# CONTROLSS_OUTPUTXBAR_CONTROLSS_OUTPUTXBAR register map
Vendor: Texas Instruments
Peripheral module from a debugger description file (folder AM263).
Registers are 32-bit, read-write, reset 0x0 unless marked. A register's access mark holds for its fields unless they carry their own. Offsets are as the file gives them; lines under a group give offsets from that group; [hi:lo] are bit positions; {n}, {i} and the like mark numbered series; 'fields as' and 'values as' point back to an identical list; <NAME> marks a mode.

## CONTROLSS_OUTPUTXBAR_CONTROLSS_OUTPUTXBAR
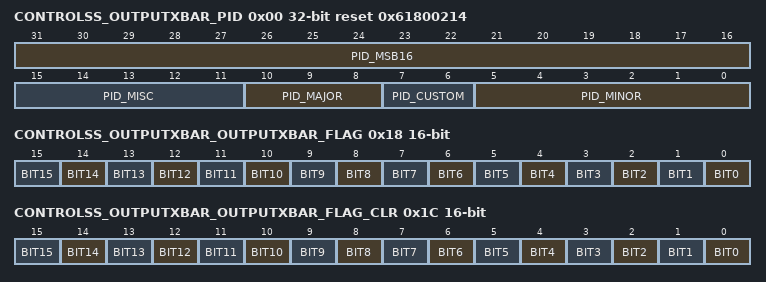
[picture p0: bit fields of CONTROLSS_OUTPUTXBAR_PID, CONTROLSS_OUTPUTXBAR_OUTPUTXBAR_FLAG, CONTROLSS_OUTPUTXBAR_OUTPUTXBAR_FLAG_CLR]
0x00 CONTROLSS_OUTPUTXBAR_PID ro reset 0x61800214
  [31:16] PID_MSB16 — Not Defined
  [15:11] PID_MISC — Not Defined
  [10:8] PID_MAJOR — Not Defined
  [7:6] PID_CUSTOM — Not Defined
  [5:0] PID_MINOR — Not Defined
0x10 CONTROLSS_OUTPUTXBAR_OUTPUTXBAR_STATUS 16-bit ro
  [15:0] STS — Status
0x14 CONTROLSS_OUTPUTXBAR_OUTPUTXBAR_FLAGINVERT 16-bit
  [15:0] INVERT — FlagInvert
0x18 CONTROLSS_OUTPUTXBAR_OUTPUTXBAR_FLAG 16-bit
  [n] BIT{n} (n=0..15) — output xbar flag
0x1C CONTROLSS_OUTPUTXBAR_OUTPUTXBAR_FLAG_CLR 16-bit
  [n] BIT{n} (n=0..15) — output xbar flag clear
0x20 CONTROLSS_OUTPUTXBAR_OUTPUTXBAR_FLAGFORCE 16-bit
  [15:0] FRC — FlagForce
0x24 CONTROLSS_OUTPUTXBAR_OUTPUTXBAR_OUTLATCH 16-bit
  [15:0] LATCHSEL — OutLatch
0x28 CONTROLSS_OUTPUTXBAR_OUTPUTXBAR_OUTSTRETCH 16-bit
  [15:0] STRETCHSEL — OutStretch
0x2C CONTROLSS_OUTPUTXBAR_OUTPUTXBAR_OUTLENGTH 16-bit
  [15:0] LENGTHSEL — OutLength
0x30 CONTROLSS_OUTPUTXBAR_OUTPUTXBAR_OUTINVERT 16-bit
{0x100+0x40*i} CONTROLSS_OUTPUTXBAR_OUTPUTXBAR{i}_G0 (i=0..15)
  [31:0] SEL — G0: PWM XBar{i} G0 input bit select. Input source is PWM[x].TRIPOUT1: PWM[x] TRIPOUT selected0: PWM[x] TRIPOUT is de-selected
{0x104+0x40*i} CONTROLSS_OUTPUTXBAR_OUTPUTXBAR{i}_G1 (i=0..15)
  [31:0] SEL — G1: OUTPUT XBar{i} G1 input bit select. Input source is PWM[x].SOCA1: PWM[x] SOCA selected0: PWM[x] SOCA is de-selected
{0x108+0x40*i} CONTROLSS_OUTPUTXBAR_OUTPUTXBAR{i}_G2 (i=0..15)
  [31:0] SEL — G2: OUTPUT XBar{i} G2 input bit select. Input source is PWM[x].SOCB1: PWM[x] SOCB selected0: PWM[x] SOCB is de-selected
{0x10C+0x40*i} CONTROLSS_OUTPUTXBAR_OUTPUTXBAR{i}_G3 (i=0..15)
  [31:0] SEL — G3: OUTPUT XBar{i} G3 input bit select. Input source is DEL[x].ACTIVE1: DEL[x] ACTIVE selected0: DEL[x] ACTIVE is de-selected
{0x110+0x40*i} CONTROLSS_OUTPUTXBAR_OUTPUTXBAR{i}_G4 (i=0..15)
  [31:0] SEL — G4: OUTPUT XBar{i} G4 input bit select. Input source is DEL[x].TRIP1: DEL[x] TRIP selected0: DEL[x] TRIP is de-selected
{0x114+0x40*i} CONTROLSS_OUTPUTXBAR_OUTPUTXBAR{i}_G5 24-bit (i=0..15)
  [23:0] SEL — G5: OUTPUT XBar{i} G5 input bit select.0: SDFM0.FILT1CEVT11: SDFM0.FILT1CEVT22: SDFM0.FILT1COMPHZ3: SDFM0.FILT2CEVT14: SDFM0.FILT2CEVT25: SDFM0.FILT2COMPHZ6: SDFM0.FILT3CEVT17: SDFM0.FILT3CEVT28: SDFM0.FILT3COMPHZ9: SDFM0.FILT4CEVT110: SDFM0.FILT4CEVT211: SDFM0.FILT4COMPHZ12: SDFM1.FILT1CEVT113: SDFM1.FILT1CEVT214: SDFM1.FILT1COMPHZ15: SDFM1.FILT2CEVT116: SDFM1.FILT2CEVT217: SDFM1.FILT2COMPHZ18: SDFM1.FILT3CEVT119: SDFM1.FILT3CEVT220: SDFM1.FILT3COMPHZ21: SDFM1.FILT4CEVT122: SDFM1.FILT4CEVT223: SDFM1.FILT4COMPHZ
{0x118+0x40*i} CONTROLSS_OUTPUTXBAR_OUTPUTXBAR{i}_G6 24-bit (i=0..15)
  [19:0] SEL — G6: OUTPUT XBar{i} G6 Input Select0: CMP12SS0.CTRIPOUTL1: CMP12SS0.CTRIPOUTH2: CMP12SS1.CTRIPOUTL3: CMP12SS1.CTRIPOUTH4: CMP12SS2.CTRIPOUTL5: CMP12SS2.CTRIPOUTH6: CMP12SS3.CTRIPOUTL7: CMP12SS3.CTRIPOUTH8: CMP12SS4.CTRIPOUTL9: CMP12SS4.CTRIPOUTH10: CMP12SS5.CTRIPOUTL11: CMP12SS5.CTRIPOUTH12: CMP12SS6.CTRIPOUTL13: CMP12SS6.CTRIPOUTH14: CMP12SS7.CTRIPOUTL15: CMP12SS7.CTRIPOUTH16: CMP12SS8.CTRIPOUTL17: CMP12SS8.CTRIPOUTH18: CMP12SS9.CTRIPOUTL19: CMP12SS9.CTRIPOUTH
{0x11C+0x40*i} CONTROLSS_OUTPUTXBAR_OUTPUTXBAR{i}_G7 24-bit (i=0..15)
  [19:0] SEL — G7: OUTPUT XBar{i} G7 Input Select0: CMP8SS0.CTRIPOUTL1: CMP8SS0.CTRIPOUTH2: CMP8SS1.CTRIPOUTL3: CMP8SS1.CTRIPOUTH4: CMP8SS2.CTRIPOUTL5: CMP8SS2.CTRIPOUTH6: CMP8SS3.CTRIPOUTL7: CMP8SS3.CTRIPOUTH8: CMP8SS4.CTRIPOUTL9: CMP8SS4.CTRIPOUTH10: CMP8SS5.CTRIPOUTL11: CMP8SS5.CTRIPOUTH12: CMP8SS6.CTRIPOUTL13: CMP8SS6.CTRIPOUTH14: CMP8SS7.CTRIPOUTL15: CMP8SS7.CTRIPOUTH16: CMP8SS8.CTRIPOUTL17: CMP8SS8.CTRIPOUTH18: CMP8SS9.CTRIPOUTL19: CMP8SS9.CTRIPOUTH
{0x120+0x40*i} CONTROLSS_OUTPUTXBAR_OUTPUTXBAR{i}_G8 24-bit (i=0..15)
  [19:0] SEL — G8: OUTPUT XBar{i} G8 Input Select0: ADC0.EVT11: ADC0.EVT22: ADC0.EVT33: ADC0.EVT44: ADC1.EVT15: ADC1.EVT26: ADC1.EVT37: ADC1 EVT48: ADC2.EVT19: ADC2 EVT210: ADC2.EVT311: ADC2.EVT412: ADC3.EVT113: ADC3.EVT214: ADC3.EVT315: ADC3.EVT416: ADC4.EVT117: ADC4.EVT218: ADC4.EVT319: ADC4.EVT4
{0x124+0x40*i} CONTROLSS_OUTPUTXBAR_OUTPUTXBAR{i}_G9 24-bit (i=0..15)
  [19:0] SEL — G9: OUTPUT XBar{i} G9 Input Select0: PWMSyncOutXBar.SYNCOUT01: PWMSyncOutXBar.SYNCOUT12: PWMSyncOutXBar.SYNCOUT23: PWMSyncOutXBar.SYNCOUT34: EQEP0.I_OUT5: EQEP0.S_OUT6: EQEP1.I_OUT7: EQEP1.S_OUT8: EQEP2.I_OUT9: EQEP2.S_OUT10: ECAP0.OUT11: ECAP1.OUT12: ECAP2.OUT13: ECAP3.OUT14: ECAP4.OUT15: ECAP5.OUT16: ECAP6.OUT17: ECAP7.OUT18: ECAP8.OUT19: ECAP9.OUT
{0x128+0x40*i} CONTROLSS_OUTPUTXBAR_OUTPUTXBAR{i}_G10 16-bit (i=0..15)
  [15:0] SEL — G10: OUTPUT XBar{i} G10 Input Select3:0: FSIRX0.RX_TRIG07:4: FSIRX1.RX_TRIG011:8: FSIRX2.RX_TRIG015:12: FSIRX3.RX_TRIG0
